# ES32F36xx register map
File version: 1.0
Registers are 32-bit, read-write, reset 0x0 unless marked. A register's access mark holds for its fields unless they carry their own. Offsets are from the block's base; [hi:lo] are bit positions; {n}, {i} and the like mark numbered series; 'fields as' and 'values as' point back to an identical list.

## PMU
Base 0x40080C00
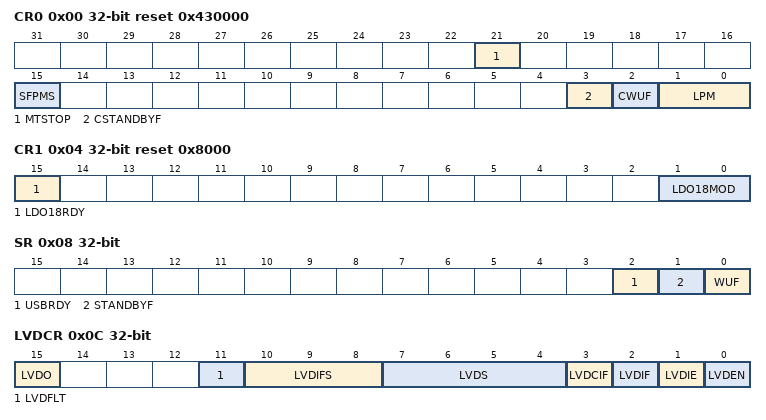
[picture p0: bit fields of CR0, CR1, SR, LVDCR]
0x00 CR0 reset 0x430000
  [21] MTSTOP, [15] SFPMS, [3] CSTANDBYF write1, [2] CWUF write1, [1:0] LPM
0x04 CR1 reset 0x8000
  [15] LDO18RDY, [1:0] LDO18MOD
0x08 SR read
  [2] USBRDY, [1] STANDBYF, [0] WUF
0x0C LVDCR
  [15] LVDO read, [11] LVDFLT, [10:8] LVDIFS, [7:4] LVDS, [3] LVDCIF write1, [2] LVDIF read, [1] LVDIE, [0] LVDEN
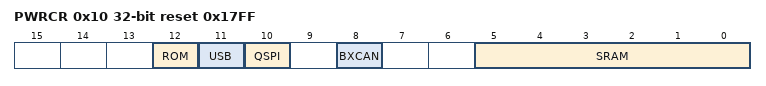
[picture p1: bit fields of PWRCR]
0x10 PWRCR reset 0x17FF
  [12] ROM, [11] USB, [10] QSPI, [8] BXCAN, [5:0] SRAM
0x20 VREFCR reset 0x7400
  [0] VREFEN

## MSC
Base 0x40081000
0x00 FLASHKEY read reset 0x3
  [1:0] STATUS
0x04 INFOKEY read reset 0x3
  [1:0] STATUS
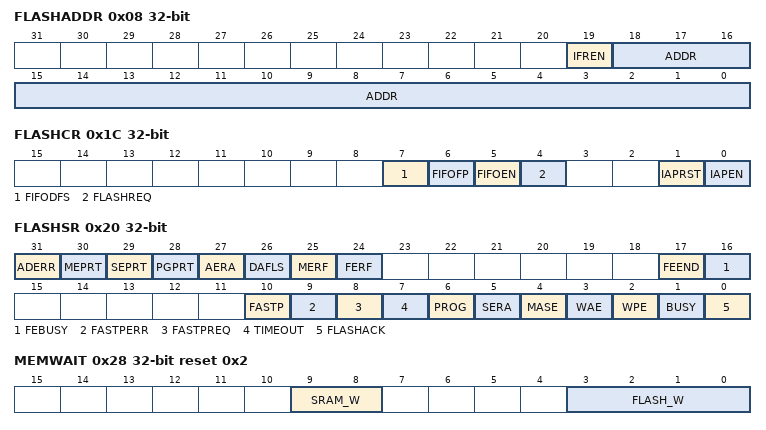
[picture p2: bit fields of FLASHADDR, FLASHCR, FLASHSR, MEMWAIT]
0x08 FLASHADDR
  [19] IFREN, [18:0] ADDR
0x0C FLASHFIFO write
  [31:0] FIFO
0x10 FLASHDL
  [31:0] DATAL
0x14 FLASHDH
  [31:0] DATAH
0x18 FLASHCMD write
  [31:0] CMD
0x1C FLASHCR
  [7] FIFODFS, [6] FIFOFP, [5] FIFOEN, [4] FLASHREQ, [1] IAPRST write1, [0] IAPEN
0x20 FLASHSR read
  [31] ADERR, [30] MEPRT, [29] SEPRT, [28] PGPRT, [27] AERA, [26] DAFLS, [25] MERF, [24] FERF, [17] FEEND, [16] FEBUSY, [10] FASTP, [9] FASTPERR, [8] FASTPREQ, [7] TIMEOUT, [6] PROG, [5] SERA, [4] MASE, [3] WAE, [2] WPE, [1] BUSY, [0] FLASHACK
0x24 FLASHPL
  [15:0] PROG_LEN
0x28 MEMWAIT reset 0x2
  [9:8] SRAM_W, [3:0] FLASH_W

## DMA
Base 0x4000C000
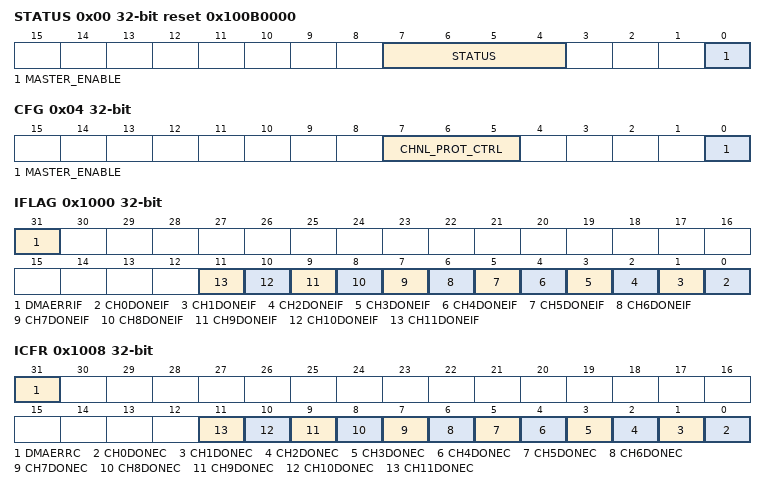
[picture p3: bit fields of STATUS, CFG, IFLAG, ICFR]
0x00 STATUS read reset 0x100B0000
  [7:4] STATUS, [0] MASTER_ENABLE
0x04 CFG write
  [7:5] CHNL_PROT_CTRL, [0] MASTER_ENABLE
0x08 CTRLBASE
  [31:9] CTRL_BASE_PTR
0x0C ALTCTRLBASE read reset 0x100
  [31:0] ALT_CTRL_BASE_PTR
0x10 CHWAITSTATUS read reset 0x3F
  [31:0] DMA_WAITONREQ_STATUS
0x14 CHSWREQ read
0x18 CHUSEBURSTSET
  [31:0] CHNL_USEBURST_SET
0x1C CHUSEBURSTCLR write
  [31:0] CHNL_USEBURST_CLR
0x20 CHREQMASKSET
  [31:0] CHNL_REQ_MASK_SET
0x24 CHREQMASKCLR write
  [31:0] CHNL_REQ_MASK_CLR
0x28 CHENSET
  [31:0] CHNL_ENABLE_SET
0x2C CHENCLR write
  [31:0] CHNL_ENABLE_CLR
0x30 CHPRIALTSET
  [31:0] CHNL_PRI_ALT_SET
0x34 CHPRIALTCLR write
  [31:0] CHNL_PRI_ALT_CLR
0x38 CHPRSET
  [31:0] CHNL_PRIORITY_SET
0x3C CHPRCLR write
  [31:0] CHNL_PRIORITY_CLR
0x4C ERRCLR
  [0] ERR_CLR
0x1000 IFLAG read
  [31] DMAERRIF, [n] CH{n}DONEIF (n=0..11)
0x1008 ICFR write1
  [31] DMAERRC, [n] CH{n}DONEC (n=0..11)
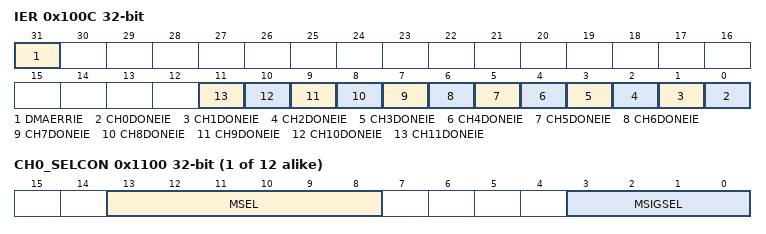
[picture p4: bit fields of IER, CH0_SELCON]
0x100C IER
  [31] DMAERRIE, [n] CH{n}DONEIE (n=0..11)
{0x1100+4i} CH{i}_SELCON (i=0..11)
  [13:8] MSEL, [3:0] MSIGSEL

## RTC
Base 0x40048400
0x00 WPR read reset 0x1
  [0] WP
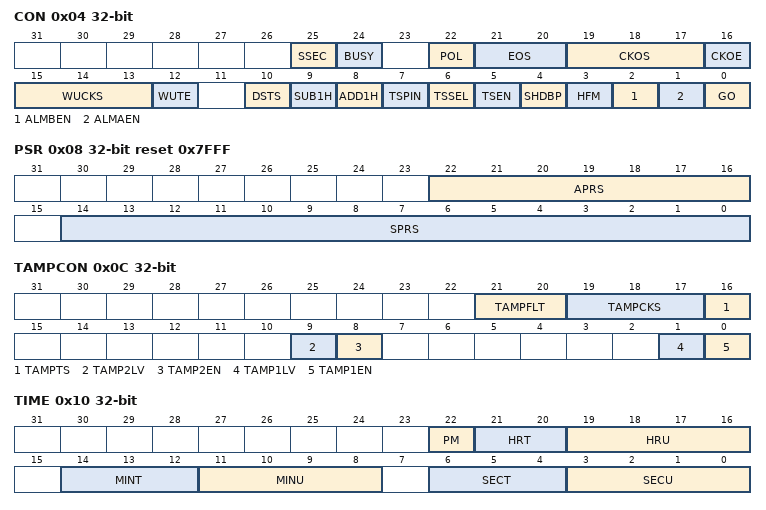
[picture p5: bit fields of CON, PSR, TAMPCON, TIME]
0x04 CON
  [25] SSEC read, [24] BUSY read, [22] POL, [21:20] EOS, [19:17] CKOS, [16] CKOE, [15:13] WUCKS, [12] WUTE, [10] DSTS, [9] SUB1H write1, [8] ADD1H write1, [7] TSPIN, [6] TSSEL, [5] TSEN, [4] SHDBP, [3] HFM, [2] ALMBEN, [1] ALMAEN, [0] GO
0x08 PSR reset 0x7FFF
  [22:16] APRS, [14:0] SPRS
0x0C TAMPCON
  [21:20] TAMPFLT, [19:17] TAMPCKS, [16] TAMPTS, [9] TAMP2LV, [8] TAMP2EN, [1] TAMP1LV, [0] TAMP1EN
0x10 TIME
  [22] PM, [21:20] HRT, [19:16] HRU, [14:12] MINT, [11:8] MINU, [6:4] SECT, [3:0] SECU
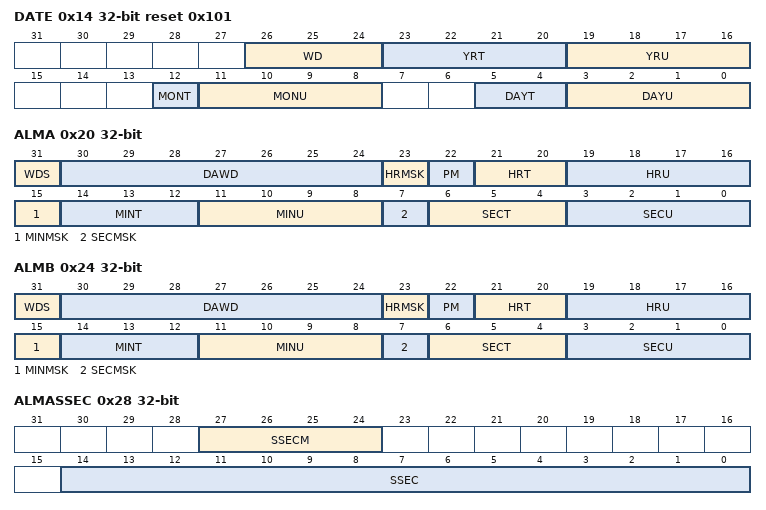
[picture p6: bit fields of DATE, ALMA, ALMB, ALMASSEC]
0x14 DATE reset 0x101
  [26:24] WD, [23:20] YRT, [19:16] YRU, [12] MONT, [11:8] MONU, [5:4] DAYT, [3:0] DAYU
0x18 SSEC read
  [15:0] VAL
0x1C WUMAT
  [15:0] VAL
0x20 ALMA
  [31] WDS, [30:24] DAWD, [23] HRMSK, [22] PM, [21:20] HRT, [19:16] HRU, [15] MINMSK, [14:12] MINT, [11:8] MINU, [7] SECMSK, [6:4] SECT, [3:0] SECU
0x24 ALMB
  fields as ALMA
0x28 ALMASSEC
  [27:24] SSECM, [14:0] SSEC
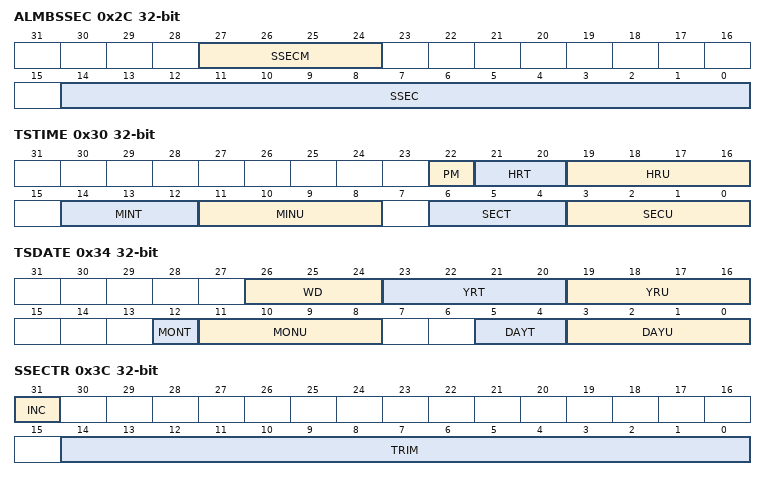
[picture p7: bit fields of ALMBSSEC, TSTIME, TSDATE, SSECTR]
0x2C ALMBSSEC
  [27:24] SSECM, [14:0] SSEC
0x30 TSTIME read
  fields as TIME
0x34 TSDATE read
  fields as DATE
0x38 TSSSEC read
  [15:0] SSEC
0x3C SSECTR write
  [31] INC, [14:0] TRIM
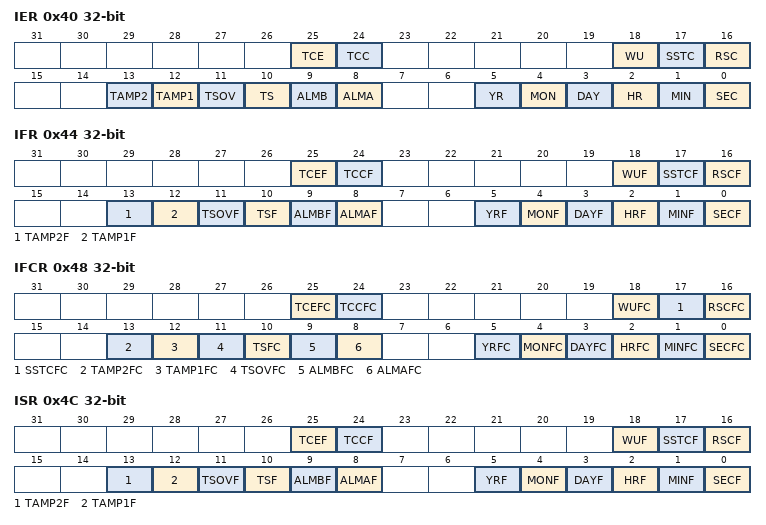
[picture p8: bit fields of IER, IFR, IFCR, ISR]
0x40 IER
  [25] TCE, [24] TCC, [18] WU, [17] SSTC, [16] RSC, [13] TAMP2, [12] TAMP1, [11] TSOV, [10] TS, [9] ALMB, [8] ALMA, [5] YR, [4] MON, [3] DAY, [2] HR, [1] MIN, [0] SEC
0x44 IFR read
  [25] TCEF, [24] TCCF, [18] WUF, [17] SSTCF, [16] RSCF, [13] TAMP2F, [12] TAMP1F, [11] TSOVF, [10] TSF, [9] ALMBF, [8] ALMAF, [5] YRF, [4] MONF, [3] DAYF, [2] HRF, [1] MINF, [0] SECF
0x48 IFCR write1
  [25] TCEFC, [24] TCCFC, [18] WUFC, [17] SSTCFC, [16] RSCFC, [13] TAMP2FC, [12] TAMP1FC, [11] TSOVFC, [10] TSFC, [9] ALMBFC, [8] ALMAFC, [5] YRFC, [4] MONFC, [3] DAYFC, [2] HRFC, [1] MINFC, [0] SECFC
0x4C ISR read
  fields as IFR
0x50 CALWPR read reset 0x1
  [0] WP
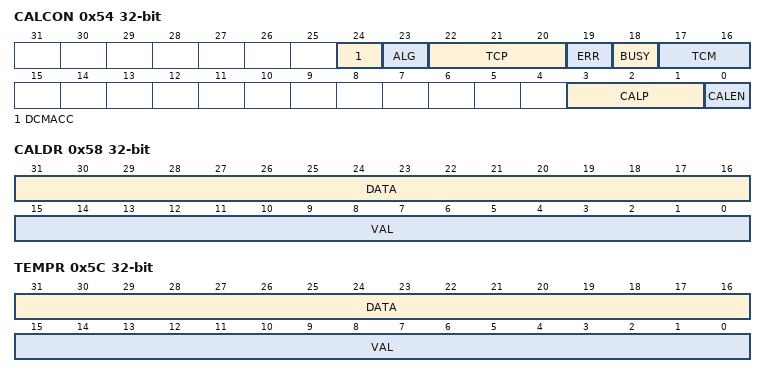
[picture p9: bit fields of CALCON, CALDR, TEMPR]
0x54 CALCON
  [24] DCMACC, [23] ALG, [22:20] TCP, [19] ERR read, [18] BUSY read, [17:16] TCM, [3:1] CALP, [0] CALEN
0x58 CALDR
  [31:16] DATA read, [15:0] VAL
0x5C TEMPR
  [31:16] DATA read, [15:0] VAL
